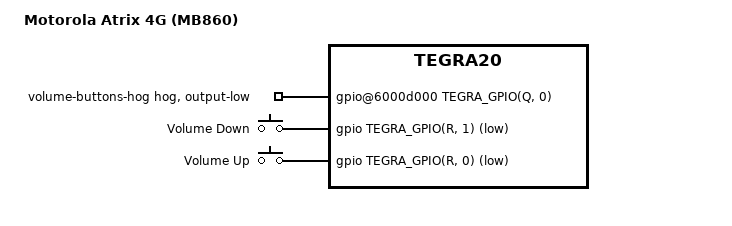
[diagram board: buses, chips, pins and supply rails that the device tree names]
// SPDX-License-Identifier: GPL-2.0
/dts-v1/;

#include "tegra20-motorola-mot.dtsi"

/ {
	model = "Motorola Atrix 4G (MB860)";
	compatible = "motorola,olympus", "nvidia,tegra20";

	gpio@6000d000 {
		volume-buttons-hog {
			gpio-hog;
			gpios = <TEGRA_GPIO(Q, 0) GPIO_ACTIVE_HIGH>;
			output-low;
		};
	};

	gpio-keys {
		compatible = "gpio-keys";

		key-volume-down {
			label = "Volume Down";
			gpios = <&gpio TEGRA_GPIO(R, 1) GPIO_ACTIVE_LOW>;
			linux,code = <KEY_VOLUMEDOWN>;
			debounce-interval = <10>;
			wakeup-event-action = <EV_ACT_ASSERTED>;
			wakeup-source;
		};

		key-volume-up {
			label = "Volume Up";
			gpios = <&gpio TEGRA_GPIO(R, 0) GPIO_ACTIVE_LOW>;
			linux,code = <KEY_VOLUMEUP>;
			debounce-interval = <10>;
			wakeup-event-action = <EV_ACT_ASSERTED>;
			wakeup-source;
		};
	};

	sound {
		nvidia,model = "Motorola Atrix 4G (MB860) CPCAP";
	};
};
